# SWM190 register map
File version: 1.0
CPU: CM0 r1p0, little endian, 2 interrupt priority bits
Registers are 32-bit, read-write, no defined reset value unless marked. A register's access mark holds for its fields unless they carry their own. Offsets are from the block's base; [hi:lo] are bit positions; lines under a group give offsets from that group; {n}, {i} and the like mark numbered series; 'fields as' and 'values as' point back to an identical list.

## GPIOA — Registers group
Base 0x40040000
Same registers: GPIOB 0x40040800, GPIOC 0x40041000, GPIOD 0x40041800, GPIOE 0x400A1000
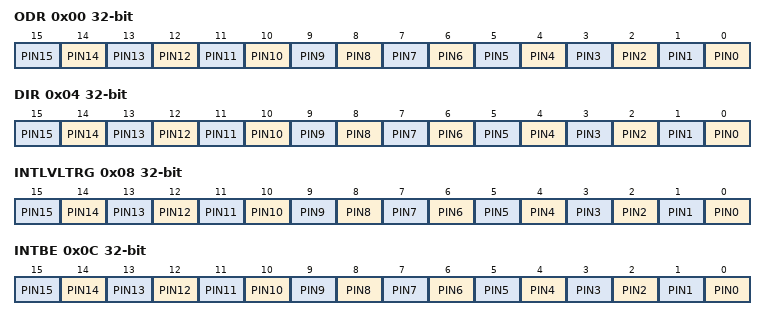
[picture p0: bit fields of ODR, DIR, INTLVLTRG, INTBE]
0x00 ODR
  [n] PIN{n} (n=0..15)
0x04 DIR
  [n] PIN{n} (n=0..15)
0x08 INTLVLTRG
  [n] PIN{n} (n=0..15)
0x0C INTBE
  [n] PIN{n} (n=0..15)
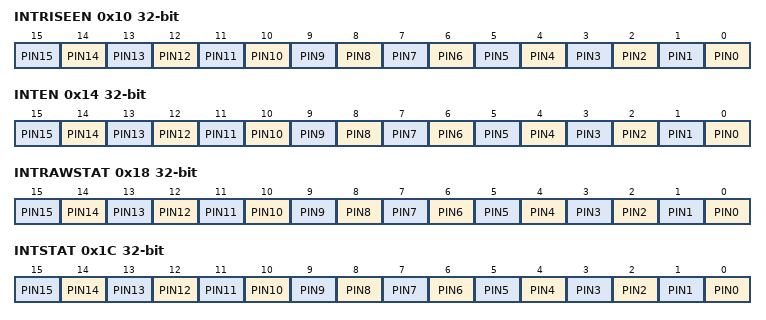
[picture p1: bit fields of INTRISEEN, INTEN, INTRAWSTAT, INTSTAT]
0x10 INTRISEEN
  [n] PIN{n} (n=0..15)
0x14 INTEN
  [n] PIN{n} (n=0..15)
0x18 INTRAWSTAT
  [n] PIN{n} (n=0..15)
0x1C INTSTAT
  [n] PIN{n} (n=0..15)
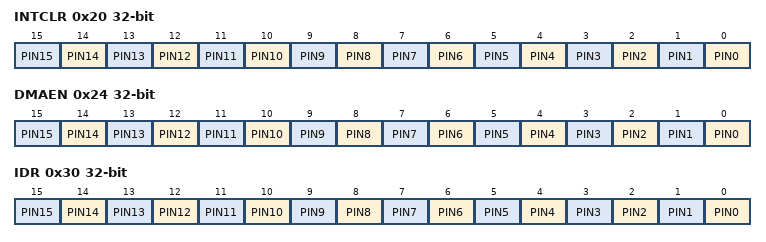
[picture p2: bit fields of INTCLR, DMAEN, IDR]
0x20 INTCLR
  [n] PIN{n} (n=0..15)
0x24 DMAEN
  [n] PIN{n} (n=0..15)
0x30 IDR
  [n] PIN{n} (n=0..15)
{0x40+4i} DATAPIN{i} (i=0..15)

## TIMR0 — Registers group
Base 0x40046800
Same registers: TIMR1 0x40046840, TIMR2 0x40046880, TIMR3 0x400468C0, BTIMR0 0x40048800, BTIMR1 0x40048840, BTIMR2 0x40048880, BTIMR3 0x400488C0
0x00 LOAD
  [24] LOAD
0x04 VALUE ro
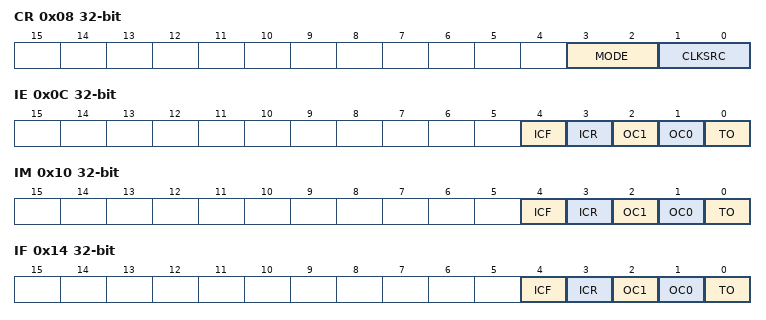
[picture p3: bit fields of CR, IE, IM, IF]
0x08 CR
  [3:2] MODE, [1:0] CLKSRC
0x08 PREDIV (alternate view of CR)
0x0C IE
  [4] ICF, [3] ICR, [2] OC1, [1] OC0, [0] TO
0x10 IM
  [4] ICF, [3] ICR, [2] OC1, [1] OC0, [0] TO
0x14 IF
  [4] ICF, [3] ICR, [2] OC1, [1] OC0, [0] TO
0x18 HALT
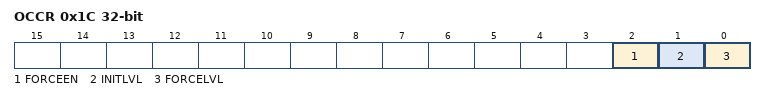
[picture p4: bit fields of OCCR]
0x1C OCCR
  [2] FORCEEN, [1] INITLVL, [0] FORCELVL
0x20 OCMAT0
0x24 OCMAT1
0x28 ICLOW
0x2C ICHIGH

## TIMRG — Registers group
Base 0x40046C00
Same registers: BTIMRG 0x40048C00
0x00 HALLIE
0x04 HALLIM
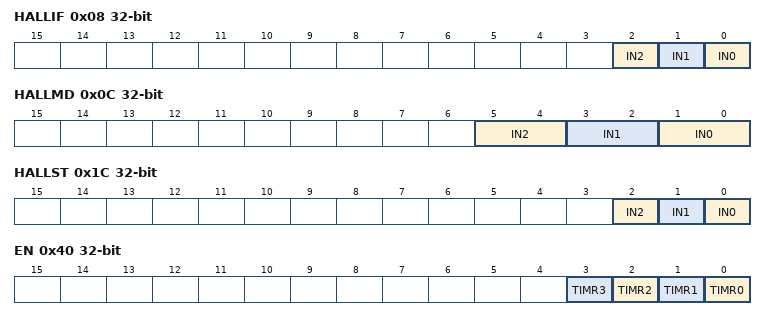
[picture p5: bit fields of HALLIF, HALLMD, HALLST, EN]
0x08 HALLIF
  [2] IN2, [1] IN1, [0] IN0
0x0C HALLMD
  [5:4] IN2, [3:2] IN1, [1:0] IN0
{0x10+4i} HALLV{i} (i=0..2)
0x1C HALLST
  [2] IN2, [1] IN1, [0] IN0
0x40 EN
  [n] TIMR{n} (n=0..3)

## UART0 — Registers group
Base 0x40042000
Same registers: UART1 0x40042800, UART2 0x40043000, UART3 0x40043800
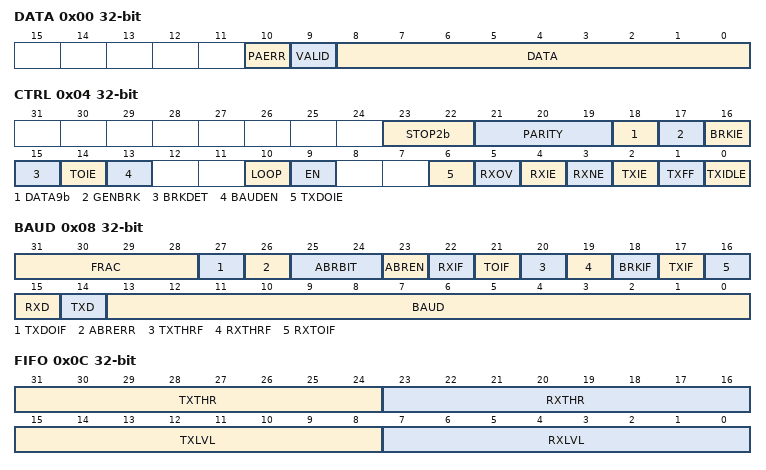
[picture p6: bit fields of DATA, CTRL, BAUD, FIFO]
0x00 DATA
  [10] PAERR, [9] VALID, [8:0] DATA
0x04 CTRL
  [23:22] STOP2b, [21:19] PARITY, [18] DATA9b, [17] GENBRK, [16] BRKIE, [15] BRKDET, [14] TOIE, [13] BAUDEN, [10] LOOP, [9] EN, [6] TXDOIE, [5] RXOV, [4] RXIE, [3] RXNE, [2] TXIE, [1] TXFF, [0] TXIDLE
0x08 BAUD
  [31:28] FRAC, [27] TXDOIF, [26] ABRERR, [25:24] ABRBIT, [23] ABREN, [22] RXIF, [21] TOIF, [20] TXTHRF, [19] RXTHRF, [18] BRKIF, [17] TXIF, [16] RXTOIF, [15] RXD, [14] TXD, [13:0] BAUD
0x0C FIFO
  [31:24] TXTHR, [23:16] RXTHR, [15:8] TXLVL, [7:0] RXLVL
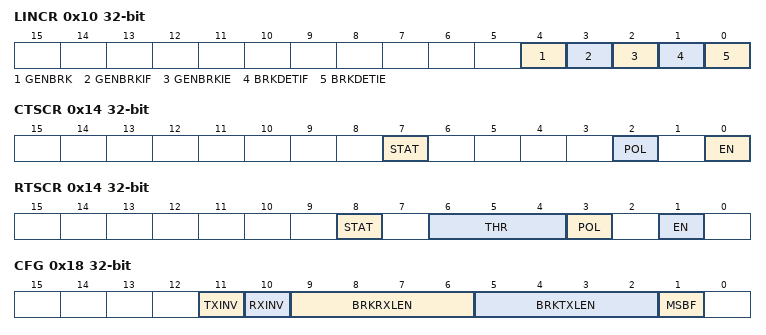
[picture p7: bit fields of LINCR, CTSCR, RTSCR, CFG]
0x10 LINCR
  [4] GENBRK, [3] GENBRKIF, [2] GENBRKIE, [1] BRKDETIF, [0] BRKDETIE
0x14 CTSCR
  [7] STAT, [2] POL, [0] EN
0x14 RTSCR (alternate view of CTSCR)
  [8] STAT, [6:4] THR, [3] POL, [1] EN
0x18 CFG
  [11] TXINV, [10] RXINV, [9:6] BRKRXLEN, [5:2] BRKTXLEN, [1] MSBF
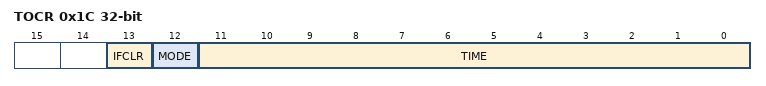
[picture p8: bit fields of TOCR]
0x1C TOCR
  [13] IFCLR, [12] MODE, [11:0] TIME

## SPI0 — Registers group
Base 0x40044000
Same registers: SPI1 0x40044800
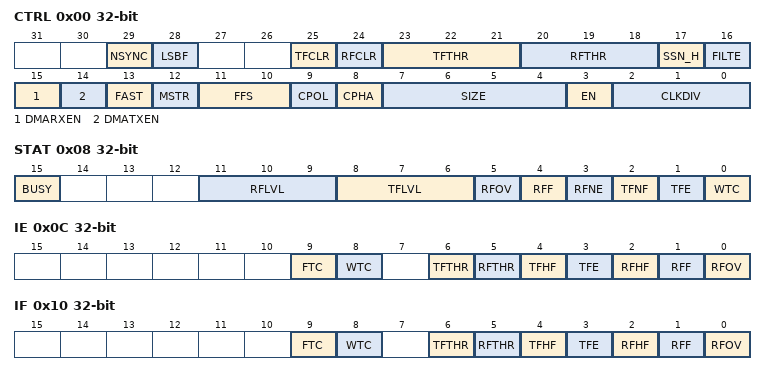
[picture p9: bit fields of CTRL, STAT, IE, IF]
0x00 CTRL
  [29] NSYNC, [28] LSBF, [25] TFCLR, [24] RFCLR, [23:21] TFTHR, [20:18] RFTHR, [17] SSN_H, [16] FILTE, [15] DMARXEN, [14] DMATXEN, [13] FAST, [12] MSTR, [11:10] FFS, [9] CPOL, [8] CPHA, [7:4] SIZE, [3] EN, [2:0] CLKDIV
0x04 DATA
0x08 STAT
  [15] BUSY, [11:9] RFLVL, [8:6] TFLVL, [5] RFOV, [4] RFF, [3] RFNE, [2] TFNF, [1] TFE, [0] WTC
0x0C IE
  [9] FTC, [8] WTC, [6] TFTHR, [5] RFTHR, [4] TFHF, [3] TFE, [2] RFHF, [1] RFF, [0] RFOV
0x10 IF
  fields as IE
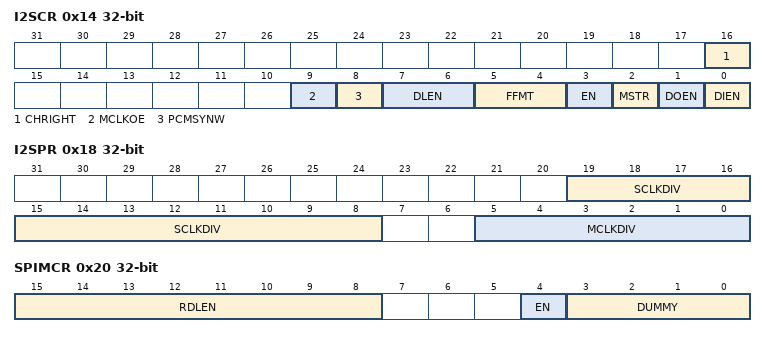
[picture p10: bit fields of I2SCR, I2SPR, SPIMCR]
0x14 I2SCR
  [16] CHRIGHT, [9] MCLKOE, [8] PCMSYNW, [7:6] DLEN, [5:4] FFMT, [3] EN, [2] MSTR, [1] DOEN, [0] DIEN
0x18 I2SPR
  [19:8] SCLKDIV, [5:0] MCLKDIV
0x20 SPIMCR
  [15:8] RDLEN, [4] EN, [3:0] DUMMY

## I2C0 — Registers group
Base 0x400A6000
Same registers: I2C1 0x400A6800
0x00 CLKDIV
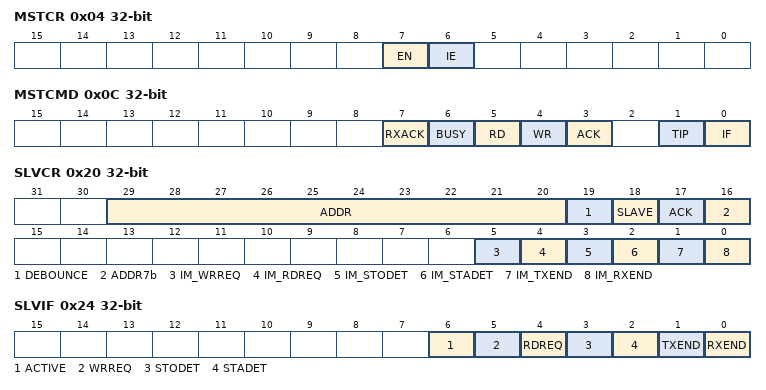
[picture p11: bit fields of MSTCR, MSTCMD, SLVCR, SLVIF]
0x04 MSTCR
  [7] EN, [6] IE
0x08 MSTDAT
0x0C MSTCMD
  [7] RXACK, [6] BUSY, [5] RD, [4] WR, [3] ACK, [1] TIP, [0] IF
0x20 SLVCR
  [29:20] ADDR, [19] DEBOUNCE, [18] SLAVE, [17] ACK, [16] ADDR7b, [5] IM_WRREQ, [4] IM_RDREQ, [3] IM_STODET, [2] IM_STADET, [1] IM_TXEND, [0] IM_RXEND
0x24 SLVIF
  [6] ACTIVE, [5] WRREQ, [4] RDREQ, [3] STODET, [2] STADET, [1] TXEND, [0] RXEND
0x28 SLVTX
0x2C SLVRX
0x30 SLVAM
